VERSION ""

NS_ :

BS_:

BU_:

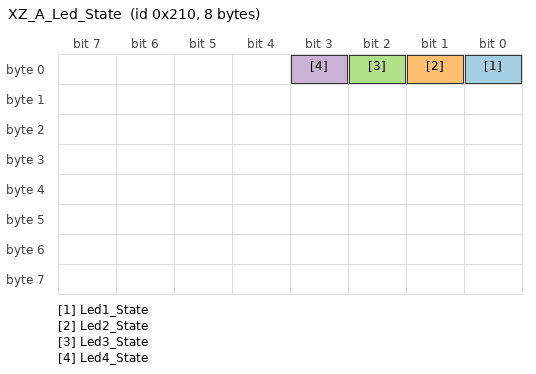
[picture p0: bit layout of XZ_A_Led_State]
BO_ 528 XZ_A_Led_State: 8 XZ_A

 SG_ Led1_State : 0|1@0+ (1,0) [0.0|1.0] ""  XZ_B

 SG_ Led2_State : 1|1@0+ (1,0) [0.0|1.0] ""  XZ_B

 SG_ Led3_State : 2|1@0+ (1,0) [0.0|1.0] ""  XZ_B

 SG_ Led4_State : 3|1@0+ (1,0) [0.0|1.0] ""  XZ_B

BA_DEF_ BU_  "TimeQuantaCANFDMax" INT 4 257;
BA_DEF_ BU_  "TimeQuantaCANFDMin" INT 4 257;
BA_DEF_ BU_  "TimeQuantaMax" INT 4 257;
BA_DEF_ BU_  "TimeQuantaMin" INT 4 257;
BA_DEF_ BU_  "SSPOffsetCANFDMax" FLOAT 50 99.9;
BA_DEF_ BU_  "SSPOffsetCANFDMin" FLOAT 50 99.9;
BA_DEF_ BU_  "SamplePointCANFDMax" FLOAT 50 99.9;
BA_DEF_ BU_  "SamplePointCANFDMin" FLOAT 50 99.9;
BA_DEF_ BU_  "SyncJumpWidthCANFDMax" FLOAT 0 50;
BA_DEF_ BU_  "SyncJumpWidthCANFDMin" FLOAT 0 50;
BA_DEF_  "BaudrateCANFD" INT 1 16000000;
BA_DEF_ SG_  "GenSigSwitchedByIgnition" ENUM  "No","Yes";
BA_DEF_ SG_  "GenSigFuncType" ENUM  "NoFunction","MsgCounter","CRC-8","XOR","XOR-2","DatedBit","SW-Kl15","CHK","Constant","Protocol","CRC-8-SAE_J1850","CRC-32","DataLength","DataID","MsgCounter16","SOK-Signatur","Cluster";
BA_DEF_ BO_  "MsgType" ENUM  "Application","NM ","NMH","TP2.0","ISO-TP ","BAP","EID","KS","XCP_PRE_CONFIGURED","XCP_RUNTIME_CONFIGURED";
BA_DEF_ BU_  "NmhNode" ENUM  "No","Yes";
BA_DEF_ BU_  "ECUVariantDefault" ENUM  "No","Yes";
BA_DEF_ BU_  "GenNodAutoGenSnd" ENUM  "No","Yes";
BA_DEF_ BU_  "GenNodAutoGenDsp" ENUM  "No","Yes";
BA_DEF_  "NmhLongTimer" INT 0 65535;
BA_DEF_  "NmhPrepareBusSleepTimer" INT 0 65535;
BA_DEF_  "NmhWaitBusSleepTimer" INT 0 65535;
BA_DEF_  "NmhTimeoutTimer" INT 0 65535;
BA_DEF_  "NBTMax" INT 1 30;
BA_DEF_  "NBTMin" INT 1 30;
BA_DEF_  "SyncJumpWidthMax" INT 1 4;
BA_DEF_  "SyncJumpWidthMin" INT 1 4;
BA_DEF_  "SamplePointMax" INT 1 100;
BA_DEF_  "SamplePointMin" INT 1 100;
BA_DEF_  "Baudrate" INT 1 1000000;
BA_DEF_  "VersionYear" INT 0 99;
BA_DEF_  "VersionWeek" INT 1 52;
BA_DEF_  "VersionMonth" INT 1 12;
BA_DEF_  "VersionDay" INT 1 31;
BA_DEF_  "NmhMessageCount" INT 0 1024;
BA_DEF_  "NmhBaseAddress" HEX 0 536870911;
BA_DEF_  "Manufacturer" STRING ;
BA_DEF_  "DBName" STRING ;
BA_DEF_  "BusType" STRING ;
BA_DEF_  "GenEnvVarEndingDsp" STRING ;
BA_DEF_  "GenEnvVarEndingSnd" STRING ;
BA_DEF_  "GenEnvVarPrefix" STRING ;
BA_DEF_  "GenNWMApBusSleep" STRING ;
BA_DEF_  "GenNWMApCanNormal" STRING ;
BA_DEF_  "GenNWMApCanOff" STRING ;
BA_DEF_  "GenNWMApCanOn" STRING ;
BA_DEF_  "GenNWMApCanSleep" STRING ;
BA_DEF_  "GenNWMApCanWakeUp" STRING ;
BA_DEF_  "GenNWMGotoMode_Awake" STRING ;
BA_DEF_  "GenNWMGotoMode_BusSleep" STRING ;
BA_DEF_  "GenNWMTalkNM" STRING ;
BA_DEF_ BU_  "NodeLayerModules" STRING ;
BA_DEF_ BU_  "ILUsed" ENUM  "No","Yes";
BA_DEF_ BO_  "GenMsgILSupport" ENUM  "No","Yes";
BA_DEF_ BO_  "GenMsgCycleTime" INT 0 65535;
BA_DEF_ BO_  "GenMsgMinAcceptLength" INT 0 8;
BA_DEF_ BO_  "GenMsgSendType" ENUM  "Cyclic","CyclicAndSpontanX","Event";
BA_DEF_ BO_  "CANFD_BRS" ENUM  "0","1";
BA_DEF_ BO_  "VFrameFormat" ENUM  "StandardCAN","ExtendedCAN","reserved","reserved","reserved","reserved","reserved","reserved","reserved","reserved","reserved","reserved","reserved","reserved","StandardCAN_FD","ExtendedCAN_FD";
BA_DEF_ SG_  "GenSigEnvVarType" ENUM  "undef","int","float";
BA_DEF_ SG_  "GenSigSendType" ENUM  "Cyclic","OnWrite","OnWriteWithRepetition","OnChange","OnChangeWithRepetition","IfActive","IfActiveWithRepetition","NoSigSendType","NotUsed","NotUsed","NotUsed","NotUsed","NotUsed";
BA_DEF_ SG_  "GenSigStartValue" FLOAT 0 1215752192;
BA_DEF_DEF_  "TimeQuantaCANFDMax" 40;
BA_DEF_DEF_  "TimeQuantaCANFDMin" 40;
BA_DEF_DEF_  "TimeQuantaMax" 160;
BA_DEF_DEF_  "TimeQuantaMin" 160;
BA_DEF_DEF_  "SSPOffsetCANFDMax" 75;
BA_DEF_DEF_  "SSPOffsetCANFDMin" 75;
BA_DEF_DEF_  "SamplePointCANFDMax" 75;
BA_DEF_DEF_  "SamplePointCANFDMin" 75;
BA_DEF_DEF_  "SyncJumpWidthCANFDMax" 50;
BA_DEF_DEF_  "SyncJumpWidthCANFDMin" 50;
BA_DEF_DEF_  "BaudrateCANFD" 2000000;
BA_DEF_DEF_  "GenSigSwitchedByIgnition" "Yes";
BA_DEF_DEF_  "GenSigFuncType" "NoFunction";
BA_DEF_DEF_  "MsgType" "Application";
BA_DEF_DEF_  "NmhNode" "Yes";
BA_DEF_DEF_  "ECUVariantDefault" "Yes";
BA_DEF_DEF_  "GenNodAutoGenSnd" "Yes";
BA_DEF_DEF_  "GenNodAutoGenDsp" "Yes";
BA_DEF_DEF_  "NmhLongTimer" 0;
BA_DEF_DEF_  "NmhPrepareBusSleepTimer" 2000;
BA_DEF_DEF_  "NmhWaitBusSleepTimer" 5000;
BA_DEF_DEF_  "NmhTimeoutTimer" 2000;
BA_DEF_DEF_  "NBTMax" 20;
BA_DEF_DEF_  "NBTMin" 10;
BA_DEF_DEF_  "SyncJumpWidthMax" 1;
BA_DEF_DEF_  "SyncJumpWidthMin" 1;
BA_DEF_DEF_  "SamplePointMax" 1;
BA_DEF_DEF_  "SamplePointMin" 1;
BA_DEF_DEF_  "Baudrate" 500000;
BA_DEF_DEF_  "VersionYear" 19;
BA_DEF_DEF_  "VersionWeek" 45;
BA_DEF_DEF_  "VersionMonth" 11;
BA_DEF_DEF_  "VersionDay" 8;
BA_DEF_DEF_  "NmhMessageCount" 1;
BA_DEF_DEF_  "NmhBaseAddress" 0;
BA_DEF_DEF_  "Manufacturer" "GWM";
BA_DEF_DEF_  "DBName" "V51EV_for_PT_CANFD V1_0浜ゆ祦鐗";
BA_DEF_DEF_  "BusType" "";
BA_DEF_DEF_  "GenEnvVarEndingDsp" "_d";
BA_DEF_DEF_  "GenEnvVarEndingSnd" "_s";
BA_DEF_DEF_  "GenEnvVarPrefix" "c";
BA_DEF_DEF_  "GenNWMApBusSleep" "apBusSleep()";
BA_DEF_DEF_  "GenNWMApCanNormal" "apCanNormal()";
BA_DEF_DEF_  "GenNWMApCanOff" "apCanOff()";
BA_DEF_DEF_  "GenNWMApCanOn" "apCanOn()";
BA_DEF_DEF_  "GenNWMApCanSleep" "apCanSleep()";
BA_DEF_DEF_  "GenNWMApCanWakeUp" "apCanWakeUp()";
BA_DEF_DEF_  "GenNWMGotoMode_Awake" "GotoMode_Awake()";
BA_DEF_DEF_  "GenNWMGotoMode_BusSleep" "GotoMode_BusSleep()";
BA_DEF_DEF_  "GenNWMTalkNM" "TalkNM()";
BA_DEF_DEF_  "NodeLayerModules" "CANoeILNLVector.dll";
BA_DEF_DEF_  "ILUsed" "Yes";
BA_DEF_DEF_  "GenMsgILSupport" "Yes";
BA_DEF_DEF_  "GenMsgCycleTime" 10;
BA_DEF_DEF_  "GenMsgMinAcceptLength" 8;
BA_DEF_DEF_  "GenMsgSendType" "Cyclic";
BA_DEF_DEF_  "CANFD_BRS" "1";
BA_DEF_DEF_  "VFrameFormat" "StandardCAN";
BA_DEF_DEF_  "GenSigEnvVarType" "undef";
BA_DEF_DEF_  "GenSigSendType" "Cyclic";
BA_DEF_DEF_  "GenSigStartValue" 0;

BA_ "GenMsgCycleTime" BO_ 528 20;
BA_ "GenMsgCycleTime" BO_ 528 20;
BA_ "GenMsgCycleTime" BO_ 528 20;
BA_ "GenMsgCycleTime" BO_ 528 20;

BA_ "BusType" "CAN";
    BA_ "NmhBaseAddress" 1280;
    BA_ "NmhMessageCount" 256;
    BA_ "SyncJumpWidthMin" 2;
    BA_ "SyncJumpWidthMax" 4;
    BA_ "NmhWaitBusSleepTimer" 2000;
    BA_ "NmhPrepareBusSleepTimer" 100;
    BA_ "NmhLongTimer" 200;
    BA_ "DBName" "DBCNetWork";

VAL_ 528 Led1_State 0 "LED_ON" 1 "LED_OFF";
VAL_ 528 Led2_State 0 "LED_ON" 1 "LED_OFF";
VAL_ 528 Led3_State 0 "LED_ON" 1 "LED_OFF";
VAL_ 528 Led4_State 0 "LED_ON" 1 "LED_OFF";

SIG_GROUP_ 528 XZ_A_Led_State 1 :  Led1_State Led2_State Led3_State Led4_State;
